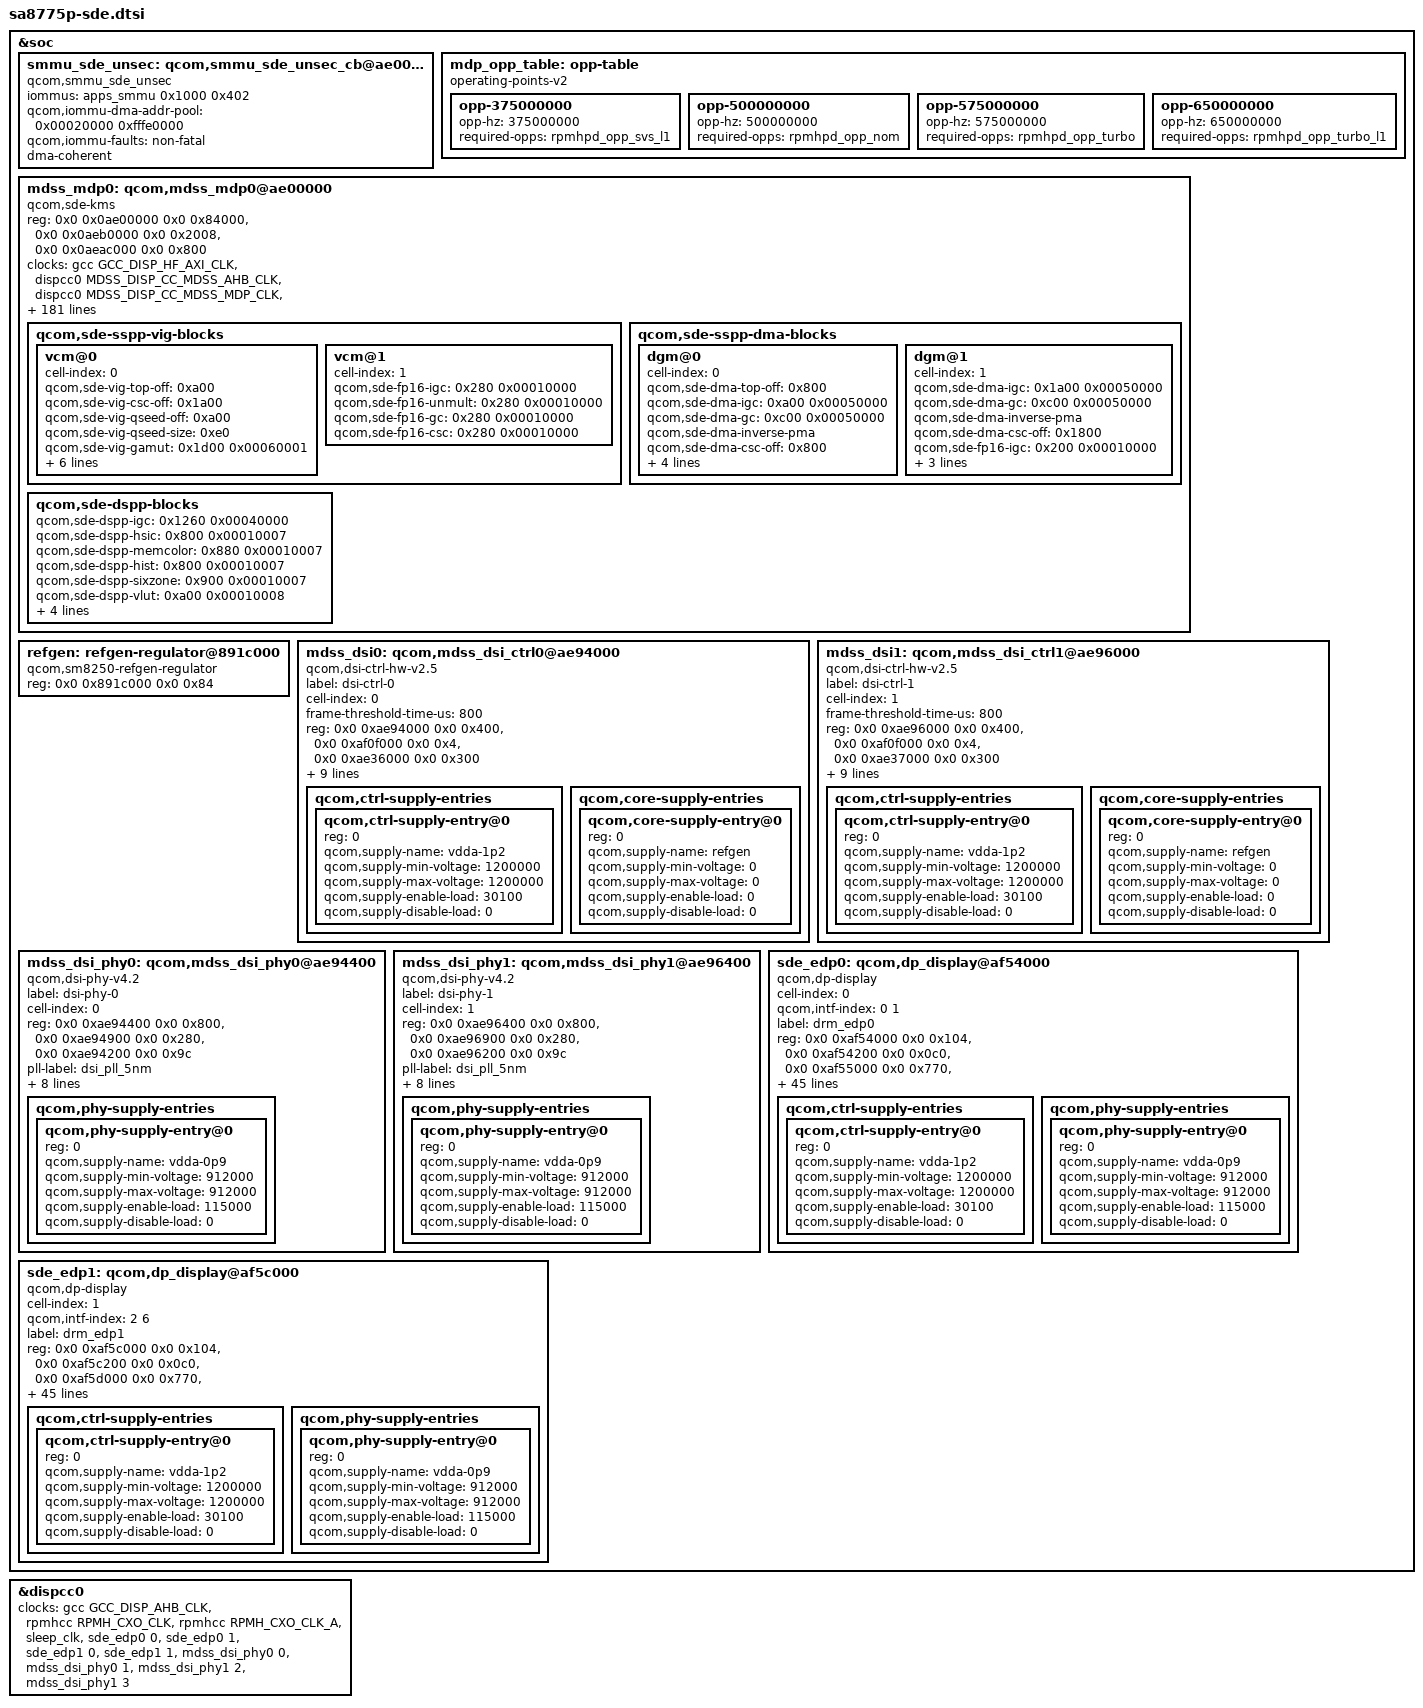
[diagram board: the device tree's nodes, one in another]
// SPDX-License-Identifier: BSD-3-Clause
/*
 * Copyright (c) 2024 Qualcomm Innovation Center, Inc. All rights reserved.
 */

#include <dt-bindings/interrupt-controller/irq.h>
#include <dt-bindings/interrupt-controller/arm-gic.h>
#include <dt-bindings/interconnect/qcom,sa8775p-rpmh.h>
#include <dt-bindings/regulator/qcom,rpmh-regulator.h>
#include <dt-bindings/clock/qcom,rpmh.h>
#include <dt-bindings/clock/qcom,sa8775p-gcc.h>
#include <dt-bindings/clock/qcom,sa8775p-dispcc.h>
#include <dt-bindings/power/qcom,rpmhpd.h>

&soc {
	smmu_sde_unsec: qcom,smmu_sde_unsec_cb@ae00000 {
		compatible = "qcom,smmu_sde_unsec";
		iommus = <&apps_smmu 0x1000 0x402>;
		qcom,iommu-dma-addr-pool = <0x00020000 0xfffe0000>;
		qcom,iommu-faults = "non-fatal";
		dma-coherent;
	};

	mdp_opp_table: opp-table {
		compatible = "operating-points-v2";

		opp-375000000 {
			opp-hz = /bits/ 64 <375000000>;
			required-opps = <&rpmhpd_opp_svs_l1>;
		};

		opp-500000000 {
			opp-hz = /bits/ 64 <500000000>;
			required-opps = <&rpmhpd_opp_nom>;
		};

		opp-575000000 {
			opp-hz = /bits/ 64 <575000000>;
			required-opps = <&rpmhpd_opp_turbo>;
		};

		opp-650000000 {
			opp-hz = /bits/ 64 <650000000>;
			required-opps = <&rpmhpd_opp_turbo_l1>;
		};
	};


	mdss_mdp0: qcom,mdss_mdp0@ae00000 {
		compatible = "qcom,sde-kms";

		reg = <0x0 0x0ae00000 0x0 0x84000>,
				<0x0 0x0aeb0000 0x0 0x2008>,
				<0x0 0x0aeac000 0x0 0x800>;
		reg-names = "mdp_phys",
				"vbif_phys",
				"regdma_phys";

		clocks = <&gcc GCC_DISP_HF_AXI_CLK>,
				<&dispcc0 MDSS_DISP_CC_MDSS_AHB_CLK>,
				<&dispcc0 MDSS_DISP_CC_MDSS_MDP_CLK>,
				<&dispcc0 MDSS_DISP_CC_MDSS_VSYNC_CLK>,
				<&dispcc0 MDSS_DISP_CC_MDSS_MDP_LUT_CLK>;
		clock-names = "gcc_bus", "iface_clk",
				"core_clk", "vsync_clk", "lut_clk";
		clock-rate = <0 0 500000000 19200000 500000000>;
		clock-max-rate = <0 0 650000000 19200000 650000000>;
		operating-points-v2 = <&mdp_opp_table>;

		power-domains = <&dispcc0 MDSS_DISP_CC_MDSS_CORE_GDSC>;
		#power-domain-cells = <1>;

		interrupts = <GIC_SPI 92 IRQ_TYPE_LEVEL_HIGH>;
		interrupt-controller;
		#interrupt-cells = <1>;

		qcom,sde-off = <0x1000>;
		qcom,sde-len = <0x494>;

		qcom,sde-ctl-off = <0x16000 0x17000 0x18000
				0x19000 0x1a000 0x1b000>;
		qcom,sde-ctl-size = <0x204>;
		qcom,sde-ctl-display-pref = "primary", "none", "none",
						"none", "none", "none";

		qcom,sde-mixer-off = <0x45000 0x46000 0x47000
						0x48000 0x49000 0x4a000
						0x0f0f 0x0f0f>;
		qcom,sde-mixer-size = <0x400>;
		qcom,sde-mixer-display-pref = "primary", "none", "none",
						"none", "none", "none", "none", "none";
		qcom,sde-mixer-dcwb-pref = "none", "none", "none", "none",
						"none", "none", "dcwb", "dcwb";

		qcom,sde-dspp-top-off = <0x1300>;
		qcom,sde-dspp-top-size = <0x80>;
		qcom,sde-dspp-off = <0x55000 0x57000 0x59000 0x5b000>;
		qcom,sde-dspp-size = <0x1800>;

		qcom,sde-dest-scaler-top-off = <0x00061000>;
		qcom,sde-dest-scaler-top-size = <0x1c>;
		qcom,sde-dest-scaler-off = <0x800 0x1000>;
		qcom,sde-dest-scaler-size = <0x800>;

		qcom,sde-wb-off = <0x66000>;
		qcom,sde-wb-size = <0x2c8>;
		qcom,sde-wb-xin-id = <6>;
		qcom,sde-wb-id = <2>;
		qcom,sde-wb-clk-ctrl = <0x2bc 16>;
		qcom,sde-wb-clk-status = <0x3bc 20>;

		qcom,sde-intf-off = <0x35000 0x36000 0x37000 0x38000
					0x39000 0x0 0x3b000 0x3c000 0x3d000>;
		qcom,sde-intf-size = <0x2c4>;
		qcom,sde-intf-type = "dp", "dsi", "dsi", "dp",
					"dp", "none", "dp", "dp", "dp";
		qcom,sde-intf-tear-irq-off = <0 0x36800 0x37800 0 0 0 0 0 0>;

		qcom,sde-pp-off = <0x6a000 0x6b000 0x6c000 0x6d000
							0x6e000 0x6f000 0x66800 0x66c00>;
		qcom,sde-pp-slave = <0x0 0x0 0x0 0x0 0x0 0x0 0x0 0x0>;
		qcom,sde-pp-size = <0xd4>;
		qcom,sde-pp-merge-3d-id = <0x0 0x0 0x1 0x1 0x2 0x2 0x3 0x3>;

		qcom,sde-merge-3d-off = <0x4f000 0x50000 0x51000 0x66f00>;
		qcom,sde-merge-3d-size = <0x10>;
		qcom,sde-pp-cwb = <0x0 0x0 0x0 0x0 0x0 0x0 0x1 0x1>;

		qcom,sde-cdm-off = <0x7a200>;
		qcom,sde-cdm-size = <0x224>;

		qcom,sde-dsc-off = <0x81000 0x81000 0x82000 0x82000 0x83000 0x83000>;
		qcom,sde-dsc-size = <0x10>;
		qcom,sde-dsc-pair-mask = <2 1 4 3 6 5>;
		qcom,sde-dsc-hw-rev = "dsc_1_2";
		qcom,sde-dsc-enc = <0x100 0x200 0x100 0x200 0x100 0x200>;
		qcom,sde-dsc-enc-size = <0x100>;
		qcom,sde-dsc-ctl = <0xF00 0xF80 0xF00 0xF80 0xF00 0xF80>;
		qcom,sde-dsc-ctl-size = <0x10>;
		qcom,sde-dsc-native422-supp = <0 0 1 1 0 0>;
		qcom,sde-dsc-linewidth = <2560>;

		qcom,sde-dither-off = <0xe0 0xe0 0xe0
					0xe0 0xe0 0xe0 0xe0 0xe0>;
		qcom,sde-cwb-dither = <0x0 0x0 0x0 0x0 0x0 0x0 0x1 0x1>;
		qcom,sde-dither-version = <0x00020000>;
		qcom,sde-dither-size = <0x20>;

		qcom,sde-sspp-type = "vig", "vig", "vig", "vig",
					"dma", "dma", "dma", "dma";

		qcom,sde-sspp-off = <0x5000 0x7000 0x9000 0xb000
					0x25000 0x27000 0x29000 0x2b000>;
		qcom,sde-sspp-src-size = <0x328>;

		qcom,sde-sspp-xin-id = <0 4 8 12 1 5 9 13>;
		qcom,sde-sspp-excl-rect = <1 1 1 1 1 1 1 1>;
		qcom,sde-sspp-smart-dma-priority = <5 6 7 8 1 2 3 4>;
		qcom,sde-smart-dma-rev = "smart_dma_v2p5";

		qcom,sde-mixer-pair-mask = <2 1 4 3 6 5 8 7>;

		qcom,sde-mixer-blend-op-off = <0x20 0x38 0x50 0x68 0x80 0x98
						0xb0 0xc8 0xe0 0xf8 0x110>;

		qcom,sde-max-per-pipe-bw-kbps = <4500000 4500000
						4500000 4500000
						4500000 4500000
						4500000 4500000>;

		qcom,sde-max-per-pipe-bw-high-kbps = <5200000 5200000
						5200000 5200000
						5200000 5200000
						5200000 5200000>;

		qcom,sde-sspp-clk-ctrl =
						<0x2ac 0>, <0x2b4 0>,
						<0x2bc 0>, <0x2c4 0>,
						<0x2ac 8>, <0x2b4 8>,
						<0x2bc 8>, <0x2c4 8>;
		qcom,sde-sspp-clk-status =
						<0x2b0 0>, <0x2b8 0>,
						<0x2c0 0>, <0x2c8 0>,
						<0x2b0 12>, <0x2b8 12>,
						<0x2c8 12>, <0x2c8 14>;
		qcom,sde-sspp-csc-off = <0x1a00>;
		qcom,sde-csc-type = "csc-10bit";
		qcom,sde-qseed-sw-lib-rev = "qseedv3lite";
		qcom,sde-qseed-scalar-version = <0x3000>;
		qcom,sde-sspp-qseed-off = <0xa00>;
		qcom,sde-mixer-linewidth = <2560>;
		qcom,sde-sspp-linewidth = <5120>;
		qcom,sde-wb-linewidth = <4096>;
		qcom,sde-wb-linewidth-linear = <5120>;
		qcom,sde-mixer-blendstages = <0xb>;
		qcom,sde-highest-bank-bit = <0x8 0x0>,
				<0x7 0x2>;
		qcom,sde-ubwc-version = <0x40000000>;
		qcom,sde-ubwc-swizzle = <0x4>;
		qcom,sde-ubwc-bw-calc-version = <0x1>;
		qcom,sde-ubwc-static = <0x1>;
		qcom,sde-macrotile-mode = <0x1>;
		qcom,sde-smart-panel-align-mode = <0xc>;
		qcom,sde-panic-per-pipe;
		qcom,sde-has-cdp;
		qcom,sde-has-src-split;
		qcom,sde-pipe-order-version = <0x1>;
		qcom,sde-has-dim-layer;

		qcom,sde-max-dest-scaler-input-linewidth = <2048>;
		qcom,sde-max-dest-scaler-output-linewidth = <2560>;
		qcom,sde-max-bw-low-kbps = <13600000>;
		qcom,sde-max-bw-high-kbps = <18200000>;
		qcom,sde-min-core-ib-kbps = <2500000>;
		qcom,sde-min-llcc-ib-kbps = <0>;
		qcom,sde-min-dram-ib-kbps = <800000>;
		qcom,sde-dram-channels = <2>;
		qcom,sde-num-nrt-paths = <0>;

		qcom,sde-lm-noise-off = <0x320>;
		qcom,sde-lm-noise-version = <0x00010000>;

		qcom,sde-vbif-off = <0>;
		qcom,sde-vbif-size = <0x1040>;
		qcom,sde-vbif-id = <0>;
		qcom,sde-vbif-memtype-0 = <3 3 3 3 3 3 3 3>;
		qcom,sde-vbif-memtype-1 = <3 3 3 3 3 3>;
		qcom,sde-vbif-default-ot-wr-limit = <16>;
		qcom,sde-vbif-dynamic-ot-wr-limit = <62208000 2 124416000 6 497664000 16>;
		qcom,sde-vbif-qos-rt-remap = <3 3 4 4 5 5 6 6 3 3 4 4 5 5 6 6>;
		qcom,sde-vbif-qos-nrt-remap = <3 3 3 3 3 3 3 3 3 3 3 3 3 3 3 3>;
		qcom,sde-vbif-qos-cwb-remap = <3 3 4 4 5 5 6 6 3 3 4 4 5 5 6 6>;
		qcom,sde-vbif-qos-lutdma-remap = <3 3 3 3 4 4 4 6 3 3 3 3 4 4 4 6>;

		qcom,sde-danger-lut = <0x3ffff 0x3ffff 0x0 0x0 0x0 0x3ffff 0x3ffff 0x0 0x0>,
					<0x3ffff 0x3ffff 0x0 0x0 0x0 0x3ffff 0x3ffff 0x0 0x0>;

		qcom,sde-safe-lut = <0xFE00 0xFE00 0xFFFF 0x1 0x3FF 0xFE00 0xFE00 0xFFFF 0xFFFF>,
					<0xFFF0 0xFFF0 0xFFFF 0x1 0x3FF 0xFFF0 0xFFF0 0xFFFF 0xFFFF>;

		qcom,sde-creq-lut = <0x00112234 0x45566777 0x00112236 0x67777777
					0x00112234 0x45566777 0x00112236 0x67777777
					0x0        0x0        0x0        0x0
					0x77776666 0x66666540 0x77776666 0x66666540
					0x77776541 0x0        0x77776541 0x0
					0x00112234 0x45566777 0x00112236 0x67777777
					0x00112234 0x45566777 0x00112236 0x67777777
					0x0        0x0        0x0        0x0
					0x0        0x0        0x0        0x0>;

		qcom,sde-cdp-setting = <1 1>, <1 0>;

		qcom,sde-qos-cpu-mask = <0x3>;
		qcom,sde-qos-cpu-mask-performance = <0xf>;
		qcom,sde-qos-cpu-dma-latency = <300>;
		qcom,sde-qos-cpu-irq-latency = <300>;

		qcom,sde-reg-dma-off = <0 0x400>;
		qcom,sde-reg-dma-id = <0 1>;
		qcom,sde-reg-dma-version = <0x00020000>;
		qcom,sde-reg-dma-trigger-off = <0x119c>;
		qcom,sde-reg-dma-xin-id = <7>;
		qcom,sde-reg-dma-clk-ctrl = <0x2bc 20>;

		qcom,sde-reg-bus,vectors-KBps = <0 0>,
						<0 74000>,
						<0 148000>,
						<0 265000>;

		interconnects = <&mmss_noc MASTER_MDP0 0 &gem_noc SLAVE_LLCC 0>,
				<&mmss_noc MASTER_MDP1 0 &gem_noc SLAVE_LLCC 0>,
				<&mc_virt MASTER_LLCC 0 &mc_virt SLAVE_EBI1 0>,
				<&gem_noc MASTER_APPSS_PROC 0 &config_noc SLAVE_DISPLAY_CFG 0>;
		interconnect-names = "qcom,sde-data-bus0", "qcom,sde-data-bus1",
				"qcom,sde-ebi-bus", "qcom,sde-reg-bus";

		qcom,sde-ib-bw-vote = <2500000 0 800000>;

		qcom,sde-sspp-vig-blocks {
			vcm@0 {
				cell-index = <0>;
				qcom,sde-vig-top-off = <0xa00>;
				qcom,sde-vig-csc-off = <0x1a00>;
				qcom,sde-vig-qseed-off = <0xa00>;
				qcom,sde-vig-qseed-size = <0xe0>;
				qcom,sde-vig-gamut = <0x1d00 0x00060001>;
				qcom,sde-vig-igc = <0x1d00 0x00060000>;
				qcom,sde-vig-inverse-pma;
				qcom,sde-fp16-igc = <0x200 0x00010000>;
				qcom,sde-fp16-unmult = <0x200 0x00010000>;
				qcom,sde-fp16-gc = <0x200 0x00010000>;
				qcom,sde-fp16-csc = <0x200 0x00010000>;
			};

			vcm@1 {
				cell-index = <1>;
				qcom,sde-fp16-igc = <0x280 0x00010000>;
				qcom,sde-fp16-unmult = <0x280 0x00010000>;
				qcom,sde-fp16-gc = <0x280 0x00010000>;
				qcom,sde-fp16-csc = <0x280 0x00010000>;
			};
		};

		qcom,sde-sspp-dma-blocks {
			dgm@0 {
				cell-index = <0>;
				qcom,sde-dma-top-off = <0x800>;
				qcom,sde-dma-igc = <0xa00 0x00050000>;
				qcom,sde-dma-gc = <0xc00 0x00050000>;
				qcom,sde-dma-inverse-pma;
				qcom,sde-dma-csc-off = <0x800>;
				qcom,sde-fp16-igc = <0x200 0x00010000>;
				qcom,sde-fp16-unmult = <0x200 0x00010000>;
				qcom,sde-fp16-gc = <0x200 0x00010000>;
				qcom,sde-fp16-csc = <0x200 0x00010000>;
			};

			dgm@1 {
				cell-index = <1>;
				qcom,sde-dma-igc = <0x1a00 0x00050000>;
				qcom,sde-dma-gc = <0xc00 0x00050000>;
				qcom,sde-dma-inverse-pma;
				qcom,sde-dma-csc-off = <0x1800>;
				qcom,sde-fp16-igc = <0x200 0x00010000>;
				qcom,sde-fp16-unmult = <0x200 0x00010000>;
				qcom,sde-fp16-gc = <0x200 0x00010000>;
				qcom,sde-fp16-csc = <0x200 0x00010000>;
			};
		};

		qcom,sde-dspp-blocks {
			qcom,sde-dspp-igc = <0x1260 0x00040000>;
			qcom,sde-dspp-hsic = <0x800 0x00010007>;
			qcom,sde-dspp-memcolor = <0x880 0x00010007>;
			qcom,sde-dspp-hist = <0x800 0x00010007>;
			qcom,sde-dspp-sixzone= <0x900 0x00010007>;
			qcom,sde-dspp-vlut = <0xa00 0x00010008>;
			qcom,sde-dspp-gamut = <0x1000 0x00040003>;
			qcom,sde-dspp-pcc = <0x1700 0x00040000>;
			qcom,sde-dspp-gc = <0x17c0 0x00010008>;
			qcom,sde-dspp-dither = <0x82c 0x00010007>;
		};
	};

	refgen: refgen-regulator@891c000 {
		compatible = "qcom,sm8250-refgen-regulator";
		reg = <0x0 0x891c000 0x0 0x84>;
	};

	mdss_dsi0: qcom,mdss_dsi_ctrl0@ae94000 {
		compatible = "qcom,dsi-ctrl-hw-v2.5";
		label = "dsi-ctrl-0";
		cell-index = <0>;
		frame-threshold-time-us = <800>;
		reg = <0x0 0xae94000 0x0 0x400>,
			<0x0 0xaf0f000 0x0 0x4>,
			<0x0 0xae36000 0x0 0x300>;
		reg-names = "dsi_ctrl", "disp_cc_base", "mdp_intf_base";
		interrupt-parent = <&mdss_mdp0>;
		interrupts = <4 0>;

		clocks = <&dispcc0 MDSS_DISP_CC_MDSS_BYTE0_CLK>,
			<&dispcc0 MDSS_DISP_CC_MDSS_BYTE0_CLK_SRC>,
			<&dispcc0 MDSS_DISP_CC_MDSS_BYTE0_INTF_CLK>,
			<&dispcc0 MDSS_DISP_CC_MDSS_PCLK0_CLK>,
			<&dispcc0 MDSS_DISP_CC_MDSS_PCLK0_CLK_SRC>,
			<&dispcc0 MDSS_DISP_CC_MDSS_ESC0_CLK>,
			<&rpmhcc RPMH_CXO_CLK>;
		clock-names = "byte_clk", "byte_clk_rcg", "byte_intf_clk",
				"pixel_clk", "pixel_clk_rcg",
				"esc_clk", "xo";

		qcom,ctrl-supply-entries {
			#address-cells = <1>;
			#size-cells = <0>;
			qcom,ctrl-supply-entry@0 {
				reg = <0>;
				qcom,supply-name = "vdda-1p2";
				qcom,supply-min-voltage = <1200000>;
				qcom,supply-max-voltage = <1200000>;
				qcom,supply-enable-load = <30100>;
				qcom,supply-disable-load = <0>;
			};
		};

		qcom,core-supply-entries {
			#address-cells = <1>;
			#size-cells = <0>;
			qcom,core-supply-entry@0 {
				reg = <0>;
				qcom,supply-name = "refgen";
				qcom,supply-min-voltage = <0>;
				qcom,supply-max-voltage = <0>;
				qcom,supply-enable-load = <0>;
				qcom,supply-disable-load = <0>;
			};
		};
	};

	mdss_dsi1: qcom,mdss_dsi_ctrl1@ae96000 {
		compatible = "qcom,dsi-ctrl-hw-v2.5";
		label = "dsi-ctrl-1";
		cell-index = <1>;
		frame-threshold-time-us = <800>;
		reg = <0x0 0xae96000 0x0 0x400>,
			<0x0 0xaf0f000 0x0 0x4>,
			<0x0 0xae37000 0x0 0x300>;
		reg-names = "dsi_ctrl", "disp_cc_base", "mdp_intf_base";
		interrupt-parent = <&mdss_mdp0>;
		interrupts = <5 0>;

		clocks = <&dispcc0 MDSS_DISP_CC_MDSS_BYTE1_CLK>,
			<&dispcc0 MDSS_DISP_CC_MDSS_BYTE1_CLK_SRC>,
			<&dispcc0 MDSS_DISP_CC_MDSS_BYTE1_INTF_CLK>,
			<&dispcc0 MDSS_DISP_CC_MDSS_PCLK1_CLK>,
			<&dispcc0 MDSS_DISP_CC_MDSS_PCLK1_CLK_SRC>,
			<&dispcc0 MDSS_DISP_CC_MDSS_ESC1_CLK>,
			<&rpmhcc RPMH_CXO_CLK>;
		clock-names = "byte_clk", "byte_clk_rcg", "byte_intf_clk",
				"pixel_clk", "pixel_clk_rcg",
				"esc_clk", "xo";

		qcom,ctrl-supply-entries {
			#address-cells = <1>;
			#size-cells = <0>;
			qcom,ctrl-supply-entry@0 {
				reg = <0>;
				qcom,supply-name = "vdda-1p2";
				qcom,supply-min-voltage = <1200000>;
				qcom,supply-max-voltage = <1200000>;
				qcom,supply-enable-load = <30100>;
				qcom,supply-disable-load = <0>;
			};
		};

		qcom,core-supply-entries {
			#address-cells = <1>;
			#size-cells = <0>;
			qcom,core-supply-entry@0 {
				reg = <0>;
				qcom,supply-name = "refgen";
				qcom,supply-min-voltage = <0>;
				qcom,supply-max-voltage = <0>;
				qcom,supply-enable-load = <0>;
				qcom,supply-disable-load = <0>;
			};
		};
	};

	mdss_dsi_phy0: qcom,mdss_dsi_phy0@ae94400 {
		compatible = "qcom,dsi-phy-v4.2";
		label = "dsi-phy-0";
		cell-index = <0>;
		#clock-cells = <1>;
		reg = <0x0 0xae94400 0x0 0x800>,
			<0x0 0xae94900 0x0 0x280>,
			<0x0 0xae94200 0x0 0x9c>;
		reg-names = "dsi_phy", "pll_base", "dyn_refresh_base";
		pll-label = "dsi_pll_5nm";

		qcom,dsi-pll-ssc-en;
		qcom,dsi-pll-ssc-mode = "down-spread";

		qcom,platform-strength-ctrl = [55 03
						55 03
						55 03
						55 03
						55 00];
		qcom,platform-lane-config = [00 00 0a 0a
						00 00 0a 0a
						00 00 0a 0a
						00 00 0a 0a
						00 00 8a 8a];
		qcom,platform-regulator-settings = [1d 1d 1d 1d 1d];

		qcom,phy-supply-entries {
			#address-cells = <1>;
			#size-cells = <0>;
			qcom,phy-supply-entry@0 {
				reg = <0>;
				qcom,supply-name = "vdda-0p9";
				qcom,supply-min-voltage = <912000>;
				qcom,supply-max-voltage = <912000>;
				qcom,supply-enable-load = <115000>;
				qcom,supply-disable-load = <0>;
			};
		};
	};

	mdss_dsi_phy1: qcom,mdss_dsi_phy1@ae96400 {
		compatible = "qcom,dsi-phy-v4.2";
		label = "dsi-phy-1";
		cell-index = <1>;
		#clock-cells = <1>;
		reg = <0x0 0xae96400 0x0 0x800>,
			<0x0 0xae96900 0x0 0x280>,
			<0x0 0xae96200 0x0 0x9c>;
		reg-names = "dsi_phy", "pll_base", "dyn_refresh_base";
		pll-label = "dsi_pll_5nm";

		qcom,dsi-pll-ssc-en;
		qcom,dsi-pll-ssc-mode = "down-spread";

		qcom,platform-strength-ctrl = [55 03
						55 03
						55 03
						55 03
						55 00];
		qcom,platform-regulator-settings = [1d 1d 1d 1d 1d];
		qcom,platform-lane-config = [00 00 0a 0a
						00 00 0a 0a
						00 00 0a 0a
						00 00 0a 0a
						00 00 8a 8a];

		qcom,phy-supply-entries {
			#address-cells = <1>;
			#size-cells = <0>;
			qcom,phy-supply-entry@0 {
				reg = <0>;
				qcom,supply-name = "vdda-0p9";
				qcom,supply-min-voltage = <912000>;
				qcom,supply-max-voltage = <912000>;
				qcom,supply-enable-load = <115000>;
				qcom,supply-disable-load = <0>;
			};
		};
	};

	sde_edp0: qcom,dp_display@af54000 {
		cell-index = <0>;
		qcom,intf-index = <0 1>;
		compatible = "qcom,dp-display";
		label = "drm_edp0";

		reg = <0x0 0xaf54000 0x0 0x104>,
				<0x0 0xaf54200 0x0 0x0c0>,
				<0x0 0xaf55000 0x0 0x770>,
				<0x0 0xaf56000 0x0 0x09c>,
				<0x0 0xaec2a00 0x0 0x200>,
				<0x0 0xaec2200 0x0 0xd0>,
				<0x0 0xaec2600 0x0 0xd0>,
				<0x0 0xaec6000 0x0 0x18>,
				<0x0 0xaf08000 0x0 0x1f4>,
				<0x0 0xaec2000 0x0 0x1c8>,
				<0x0 0xaee1000 0x0 0x030>,
				<0x0 0xaf57000 0x0 0x09c>,
				<0x0 0xaf09000 0x0 0x14>;
		reg-names = "dp_ahb", "dp_aux", "dp_link",
				"dp_p0", "dp_phy", "dp_ln_tx0", "dp_ln_tx1",
				"ahb2phy", "dp_mmss_cc", "dp_pll",
				"hdcp_physical", "dp_p1", "gdsc";

		interrupt-parent = <&mdss_mdp0>;
		interrupts = <12 0>;

		clocks = <&dispcc0 MDSS_DISP_CC_MDSS_DPTX0_AUX_CLK>,
				<&gcc GCC_EDP_REF_CLKREF_EN>,
				<&rpmhcc RPMH_CXO_CLK>,
				<&dispcc0 MDSS_DISP_CC_MDSS_DPTX0_LINK_CLK>,
				<&dispcc0 MDSS_DISP_CC_MDSS_DPTX0_LINK_CLK_SRC>,
				<&dispcc0 MDSS_DISP_CC_MDSS_DPTX0_LINK_INTF_CLK>,
				<&sde_edp0 0>,
				<&dispcc0 MDSS_DISP_CC_MDSS_DPTX0_PIXEL0_CLK_SRC>,
				<&sde_edp0 1>,
				<&dispcc0 MDSS_DISP_CC_MDSS_DPTX0_PIXEL1_CLK_SRC>,
				<&dispcc0 MDSS_DISP_CC_MDSS_DPTX0_PIXEL0_CLK>,
				<&dispcc0 MDSS_DISP_CC_MDSS_DPTX0_PIXEL1_CLK>;
		clock-names = "core_aux_clk", "core_ref_clk", "rpmh_cxo_clk",
				"link_clk", "link_clk_src", "link_iface_clk", "link_parent",
				"pixel_clk_rcg", "pixel_parent", "pixel1_clk_rcg",
				"strm0_pixel_clk", "strm1_pixel_clk";

		qcom,pll-revision = "edp-5nm";
		#clock-cells = <1>;
		qcom,phy-version = <0x500>;
		qcom,phy-mode = "edp";
		qcom,aux-cfg0-settings = [24 00];
		qcom,aux-cfg1-settings = [28 13];
		qcom,aux-cfg2-settings = [2c a4];
		qcom,aux-cfg3-settings = [30 00];
		qcom,aux-cfg4-settings = [34 0a];
		qcom,aux-cfg5-settings = [38 26];
		qcom,aux-cfg6-settings = [3c 0a];
		qcom,aux-cfg7-settings = [40 03];
		qcom,aux-cfg8-settings = [44 b7];
		qcom,aux-cfg9-settings = [48 03];

		qcom,pclk-reg-off = <0x188 0x1A0>;
		qcom,max-pclk-frequency-khz = <675000>;

		qcom,widebus-enable;
		qcom,mst-enable;
		qcom,fec-feature-enable;
		qcom,qos-cpu-mask = <0xf>;
		qcom,qos-cpu-latency-us = <300>;

		qcom,ctrl-supply-entries {
			#address-cells = <1>;
			#size-cells = <0>;

			qcom,ctrl-supply-entry@0 {
				reg = <0>;
				qcom,supply-name = "vdda-1p2";
				qcom,supply-min-voltage = <1200000>;
				qcom,supply-max-voltage = <1200000>;
				qcom,supply-enable-load = <30100>;
				qcom,supply-disable-load = <0>;
			};
		};

		qcom,phy-supply-entries {
			#address-cells = <1>;
			#size-cells = <0>;

			qcom,phy-supply-entry@0 {
				reg = <0>;
				qcom,supply-name = "vdda-0p9";
				qcom,supply-min-voltage = <912000>;
				qcom,supply-max-voltage = <912000>;
				qcom,supply-enable-load = <115000>;
				qcom,supply-disable-load = <0>;
			};
		};
	};

	sde_edp1: qcom,dp_display@af5c000 {
		cell-index = <1>;
		qcom,intf-index = <2 6>;
		compatible = "qcom,dp-display";
		label = "drm_edp1";

		reg = <0x0 0xaf5c000 0x0 0x104>,
				<0x0 0xaf5c200 0x0 0x0c0>,
				<0x0 0xaf5d000 0x0 0x770>,
				<0x0 0xaf5e000 0x0 0x09c>,
				<0x0 0xaec5a00 0x0 0x200>,
				<0x0 0xaec5200 0x0 0xd0>,
				<0x0 0xaec5600 0x0 0xd0>,
				<0x0 0xaec6000 0x0 0x18>,
				<0x0 0xaf08000 0x0 0x1f4>,
				<0x0 0xaec5000 0x0 0x1c8>,
				<0x0 0xaee2000 0x0 0x030>,
				<0x0 0xaf5f000 0x0 0x09c>,
				<0x0 0xaf09000 0x0 0x14>;
		reg-names = "dp_ahb", "dp_aux", "dp_link",
				"dp_p0", "dp_phy", "dp_ln_tx0", "dp_ln_tx1",
				"ahb2phy", "dp_mmss_cc", "dp_pll",
				"hdcp_physical", "dp_p1", "gdsc";

		interrupt-parent = <&mdss_mdp0>;
		interrupts = <13 0>;

		clocks = <&dispcc0 MDSS_DISP_CC_MDSS_DPTX1_AUX_CLK>,
				<&gcc GCC_EDP_REF_CLKREF_EN>,
				<&rpmhcc RPMH_CXO_CLK>,
				<&dispcc0 MDSS_DISP_CC_MDSS_DPTX1_LINK_CLK>,
				<&dispcc0 MDSS_DISP_CC_MDSS_DPTX1_LINK_CLK_SRC>,
				<&dispcc0 MDSS_DISP_CC_MDSS_DPTX1_LINK_INTF_CLK>,
				<&sde_edp1 0>,
				<&dispcc0 MDSS_DISP_CC_MDSS_DPTX1_PIXEL0_CLK_SRC>,
				<&sde_edp1 1>,
				<&dispcc0 MDSS_DISP_CC_MDSS_DPTX1_PIXEL1_CLK_SRC>,
				<&dispcc0 MDSS_DISP_CC_MDSS_DPTX1_PIXEL0_CLK>,
				<&dispcc0 MDSS_DISP_CC_MDSS_DPTX1_PIXEL1_CLK>;
		clock-names = "core_aux_clk", "core_ref_clk", "rpmh_cxo_clk",
				"link_clk", "link_clk_src", "link_iface_clk", "link_parent",
				"pixel_clk_rcg", "pixel_parent", "pixel1_clk_rcg",
				"strm0_pixel_clk", "strm1_pixel_clk";

		qcom,pll-revision = "edp-5nm";
		#clock-cells = <1>;
		qcom,phy-version = <0x500>;
		qcom,phy-mode = "edp";
		qcom,aux-cfg0-settings = [24 00];
		qcom,aux-cfg1-settings = [28 13];
		qcom,aux-cfg2-settings = [2c a4];
		qcom,aux-cfg3-settings = [30 00];
		qcom,aux-cfg4-settings = [34 0a];
		qcom,aux-cfg5-settings = [38 26];
		qcom,aux-cfg6-settings = [3c 0a];
		qcom,aux-cfg7-settings = [40 03];
		qcom,aux-cfg8-settings = [44 b7];
		qcom,aux-cfg9-settings = [48 03];

		qcom,pclk-reg-off = <0x1D0 0x1E8>;
		qcom,max-pclk-frequency-khz = <675000>;

		qcom,widebus-enable;
		qcom,mst-enable;
		qcom,fec-feature-enable;
		qcom,qos-cpu-mask = <0xf>;
		qcom,qos-cpu-latency-us = <300>;

		qcom,ctrl-supply-entries {
			#address-cells = <1>;
			#size-cells = <0>;

			qcom,ctrl-supply-entry@0 {
				reg = <0>;
				qcom,supply-name = "vdda-1p2";
				qcom,supply-min-voltage = <1200000>;
				qcom,supply-max-voltage = <1200000>;
				qcom,supply-enable-load = <30100>;
				qcom,supply-disable-load = <0>;
			};
		};

		qcom,phy-supply-entries {
			#address-cells = <1>;
			#size-cells = <0>;

			qcom,phy-supply-entry@0 {
				reg = <0>;
				qcom,supply-name = "vdda-0p9";
				qcom,supply-min-voltage = <912000>;
				qcom,supply-max-voltage = <912000>;
				qcom,supply-enable-load = <115000>;
				qcom,supply-disable-load = <0>;
			};
		};
	};
};

&dispcc0 {
	clocks =  <&gcc GCC_DISP_AHB_CLK>,
		<&rpmhcc RPMH_CXO_CLK>,
		<&rpmhcc RPMH_CXO_CLK_A>,
		<&sleep_clk>,
		<&sde_edp0 0>,
		<&sde_edp0 1>,
		<&sde_edp1 0>,
		<&sde_edp1 1>,
		<&mdss_dsi_phy0 0>,
		<&mdss_dsi_phy0 1>,
		<&mdss_dsi_phy1 2>,
		<&mdss_dsi_phy1 3>;
	clock-names = "iface",
		"bi_tcxo",
		"bi_tcxo_ao",
		"sleep_clk",
		"dp0_phy_pll_link_clk",
		"dp0_phy_pll_vco_div_clk",
		"dp1_phy_pll_link_clk",
		"dp1_phy_pll_vco_div_clk",
		"dsi0_phy_pll_out_byteclk",
		"dsi0_phy_pll_out_dsiclk",
		"dsi1_phy_pll_out_byteclk",
		"dsi1_phy_pll_out_dsiclk";
};
